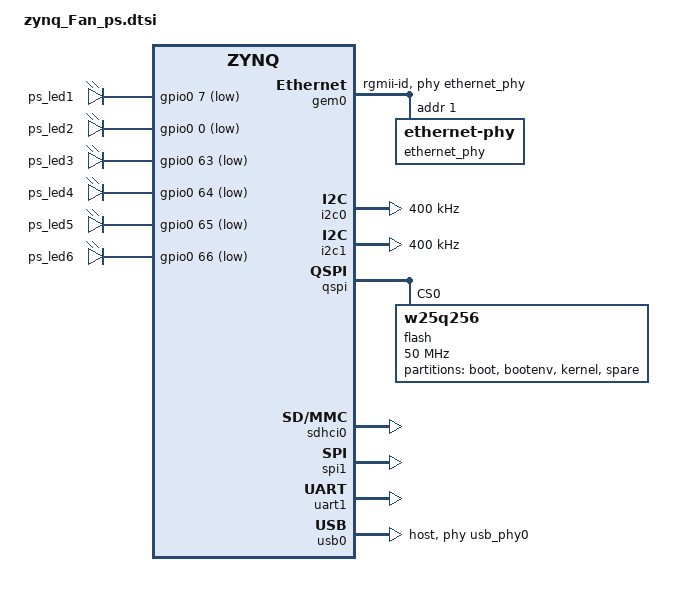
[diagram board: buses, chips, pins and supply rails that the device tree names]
/*
 * CAUTION: This file is automatically generated by Xilinx.
 * Version:  
 * Today is: Thu Jan 21 20:34:55 2021
 */

#include <dt-bindings/gpio/gpio.h>

/ {
    /*
	cpus {
		cpu@0 {
			//operating-points = <666666 1000000 333333 1000000>;
            operating-points = <766666 1000000 333333 1000000>;
		};
	};
    */
    
    leds{
        #address-cells = <1>;
        #size-cells = <0>;
        compatible = "gpio-leds";
        led@1{
            label = "ps_led1";
            reg = <1>;
            gpios = <&gpio0 7 GPIO_ACTIVE_LOW>;
            linux,default-trigger = "heartbeat";
			default-state = "off";
        };
        led@2{
            label = "ps_led2";
            reg = <2>;
            gpios = <&gpio0 0 GPIO_ACTIVE_LOW>;
            linux,default-trigger = "mmc0";
			default-state = "off";
        };
        led@3{
            label = "ps_led3";
            reg = <3>;
            gpios = <&gpio0 63 GPIO_ACTIVE_LOW>;
            linux,default-trigger = "mmc0";
			default-state = "off";
        };
        led@4{
            label = "ps_led4";
            reg = <4>;
            gpios = <&gpio0 64 GPIO_ACTIVE_LOW>;
            linux,default-trigger = "none";
            panic-indicator;
			default-state = "off";
        };
        led@5{
            label = "ps_led5";
            reg = <5>;
            gpios = <&gpio0 65 GPIO_ACTIVE_LOW>;
            linux,default-trigger = "phy0tx";
			default-state = "off";
        };
        led@6{
            label = "ps_led6";
            reg = <6>;
            gpios = <&gpio0 66 GPIO_ACTIVE_LOW>;
            linux,default-trigger = "timer";
			default-state = "on";
        };
    };
    
    usb_phy0:USB3320{
			compatible = "ulpi-phy";
            #phy-cells=<0>;
            reg = <0xe0002000 0x1000>;
            view-port = <0x0170>;
            drv-vbus;
    };
};
&gem0 {
	phy-mode = "rgmii-id";
    local-mac-address = [00 0a 35 00 00 00];
    phy-handle = <&ethernet_phy>;
	status = "okay";
	xlnx,ptp-enet-clock = <0x69f6bcb>;
    
    ethernet_phy: ethernet-phy@1{
            reg = <1>;
            device_type = "ethernet_phy";
    };
};
&gpio0 {
	emio-gpio-width = <13>;
	gpio-mask-high = <0x0>;
	gpio-mask-low = <0x5600>;
};
&i2c0 {
	clock-frequency = <400000>;
	status = "okay";
};
&i2c1 {
	clock-frequency = <400000>;
	status = "okay";
};
&intc {
	num_cpus = <2>;
	num_interrupts = <96>;
};
&qspi {
    //u-boot,dm-pre-reloc;
	is-dual = <0>;
	num-cs = <1>;
	spi-rx-bus-width = <4>;
	spi-tx-bus-width = <4>;
	status = "okay";
    flash:flash@0{
        compatible = "w25q256";
        reg = <0x0>;
        spi-rx-bus-width = <4>;
        spi-tx-bus-width = <4>;
        spi-max-frequency = <50000000>;
        #address-cells = <1>;
        #size-cells = <1>;
        partition@0x00000000{
            label = "boot";
            reg = <0x00000000 0x00500000>;
        };
        partition@0x00500000{
            label = "bootenv";
            reg = <0x00500000 0x00020000>;
        };
        partition@0x00520000{
            label = "kernel";
            reg = <0x00520000 0x00a80000>;
        };
        partition@0x00fa0000{
            label = "spare";
            reg = <0x00fa0000 0x00000000>;
        };
    };
};
&sdhci0 {
    //u-boot,dm-pre-reloc;
	status = "okay";
	xlnx,has-cd = <0x1>;
	xlnx,has-power = <0x0>;
	xlnx,has-wp = <0x0>;
};
&spi1 {
	is-decoded-cs = <0>;
	num-cs = <1>;
	status = "okay";
};
&uart1 {
    //u-boot,dm-pre-reloc;
	cts-override ;
	device_type = "serial";
	port-number = <0>;
	status = "okay";
};
&usb0 {
	phy_type = "ulpi";
    usb-phy = <&usb_phy0>;
    dr_mode = "host";
	status = "okay";
	usb-reset = <&gpio0 46 0>;
};
&clkc {
	fclk-enable = <0x3>;
	ps-clk-frequency = <33333333>;
};
